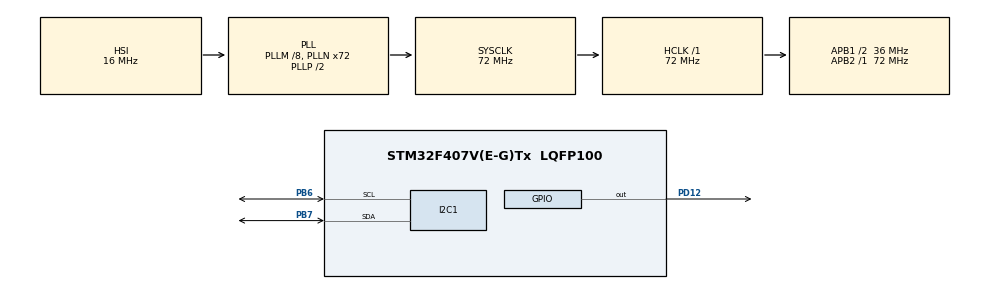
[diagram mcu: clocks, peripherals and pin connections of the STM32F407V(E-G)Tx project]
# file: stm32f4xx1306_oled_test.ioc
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I2C1.I2C_Mode=I2C_Fast
Mcu.Family=STM32F4
Mcu.Name=STM32F407V(E-G)Tx
Mcu.Package=LQFP100
NVIC.PriorityGroup=NVIC_PRIORITYGROUP_4
PB6.Mode=I2C
PB6.Signal=I2C1_SCL
PB7.Mode=I2C
PB7.Signal=I2C1_SDA
PD12.Signal=GPIO_Output
PH0-OSC_IN.Mode=HSE-External-Oscillator
PH0-OSC_IN.Signal=RCC_OSC_IN
PH1-OSC_OUT.Mode=HSE-External-Oscillator
PH1-OSC_OUT.Signal=RCC_OSC_OUT
ProjectManager.HeapSize=0x200
ProjectManager.StackSize=0x400
ProjectManager.TargetToolchain=STM32CubeIDE
RCC.48MHZClocksFreq_Value=36000000
RCC.AHBFreq_Value=72000000
RCC.APB1CLKDivider=RCC_HCLK_DIV2
RCC.APB1Freq_Value=36000000
RCC.APB1TimFreq_Value=72000000
RCC.APB2Freq_Value=72000000
RCC.APB2TimFreq_Value=72000000
RCC.CortexFreq_Value=72000000
RCC.HCLKFreq_Value=72000000
RCC.HSE_VALUE=25000000
RCC.HSI_VALUE=16000000
RCC.LSE_VALUE=32768
RCC.PLLM=8
RCC.PLLN=72
RCC.SYSCLKFreq_VALUE=72000000
RCC.SYSCLKSource=RCC_SYSCLKSOURCE_PLLCLK
RCC.VCOOutputFreq_Value=144000000
board=STM32F407G-DISC1

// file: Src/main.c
/* USER CODE BEGIN Header */
/**
  ******************************************************************************
  * @file           : main.c
  * @brief          : Main program body
  ******************************************************************************
  * @attention
  *
  * <h2><center>&copy; Copyright (c) 2020 STMicroelectronics.
  * All rights reserved.</center></h2>
  *
  * This software component is licensed by ST under BSD 3-Clause license,
  * the "License"; You may not use this file except in compliance with the
  * License. You may obtain a copy of the License at:
  *                        opensource.org/licenses/BSD-3-Clause
  *
  ******************************************************************************
  */
/* USER CODE END Header */

#include "main.h"

/* USER CODE BEGIN Includes */
#include "ssd1306.h"
#include "fonts.h"
#include "test.h"
/* USER CODE END Includes */

I2C_HandleTypeDef hi2c1;

void SystemClock_Config(void);
static void MX_GPIO_Init(void);
static void MX_I2C1_Init(void);

int main(void)
{

  /* MCU Configuration--------------------------------------------------------*/

  /* Reset of all peripherals, Initializes the Flash interface and the Systick. */
  HAL_Init();

  /* Configure the system clock */
  SystemClock_Config();

  /* Initialize all configured peripherals */
  MX_GPIO_Init();
  MX_I2C1_Init();
  /* USER CODE BEGIN 2 */
  SSD1306_Init (); // initialize the diaply

  /* USER CODE END 2 */

  /* Infinite loop */
  while (1)
  {

    /* USER CODE BEGIN 3 */
	  HAL_GPIO_TogglePin(GPIOD, GPIO_PIN_12);
	  HAL_Delay(200);

	  SSD1306_GotoXY (10,10); // goto 10, 10
	  SSD1306_Puts ("HELLO", &Font_11x18, 1); // print Hello
	  SSD1306_GotoXY (10, 30);
	  SSD1306_Puts ("I am Abhinav!!", &Font_7x10, 1);
	  SSD1306_UpdateScreen(); // update screen
//	  0x0000, 0x0000, 0x4400, 0x4400, 0x7C00, 0x2800, 0x2800, 0x2800, 0x2800, 0x1000,  // A
	  //0x1000, 0x2800, 0x2800, 0x2800, 0x2800, 0x7C00, 0x4400, 0x4400, 0x0000, 0x0000,  // A

	  SSD1306_ScrollRight(0x00, 0xff); // Scroll entire Screen screen right is divided in 7 pages (0x00 to 0xff)
	  HAL_Delay(20000);

	  SSD1306_ScrollRight(0x00, 0xff); // Scroll entire Screen screen left is divided in 7 pages (0x00 to 0xff)
	  HAL_Delay(20000);

	  SSD1306_Stopscroll();
	  SSD1306_Clear();
  }
  /* USER CODE END 3 */
}

void SystemClock_Config(void)
{
  RCC_OscInitTypeDef RCC_OscInitStruct = {0};
  RCC_ClkInitTypeDef RCC_ClkInitStruct = {0};

  /** Configure the main internal regulator output voltage
  */
  __HAL_RCC_PWR_CLK_ENABLE();
  __HAL_PWR_VOLTAGESCALING_CONFIG(PWR_REGULATOR_VOLTAGE_SCALE1);
  /** Initializes the CPU, AHB and APB busses clocks
  */
  RCC_OscInitStruct.OscillatorType = RCC_OSCILLATORTYPE_HSI;
  RCC_OscInitStruct.HSIState = RCC_HSI_ON;
  RCC_OscInitStruct.HSICalibrationValue = RCC_HSICALIBRATION_DEFAULT;
  RCC_OscInitStruct.PLL.PLLState = RCC_PLL_ON;
  RCC_OscInitStruct.PLL.PLLSource = RCC_PLLSOURCE_HSI;
  RCC_OscInitStruct.PLL.PLLM = 8;
  RCC_OscInitStruct.PLL.PLLN = 72;
  RCC_OscInitStruct.PLL.PLLP = RCC_PLLP_DIV2;
  RCC_OscInitStruct.PLL.PLLQ = 4;
  if (HAL_RCC_OscConfig(&RCC_OscInitStruct) != HAL_OK)
  {
    Error_Handler();
  }
  /** Initializes the CPU, AHB and APB busses clocks
  */
  RCC_ClkInitStruct.ClockType = RCC_CLOCKTYPE_HCLK|RCC_CLOCKTYPE_SYSCLK
                              |RCC_CLOCKTYPE_PCLK1|RCC_CLOCKTYPE_PCLK2;
  RCC_ClkInitStruct.SYSCLKSource = RCC_SYSCLKSOURCE_PLLCLK;
  RCC_ClkInitStruct.AHBCLKDivider = RCC_SYSCLK_DIV1;
  RCC_ClkInitStruct.APB1CLKDivider = RCC_HCLK_DIV2;
  RCC_ClkInitStruct.APB2CLKDivider = RCC_HCLK_DIV1;

  if (HAL_RCC_ClockConfig(&RCC_ClkInitStruct, FLASH_LATENCY_2) != HAL_OK)
  {
    Error_Handler();
  }
}

static void MX_I2C1_Init(void)
{

  hi2c1.Instance = I2C1;
  hi2c1.Init.ClockSpeed = 400000;
  hi2c1.Init.DutyCycle = I2C_DUTYCYCLE_2;
  hi2c1.Init.OwnAddress1 = 0;
  hi2c1.Init.AddressingMode = I2C_ADDRESSINGMODE_7BIT;
  hi2c1.Init.DualAddressMode = I2C_DUALADDRESS_DISABLE;
  hi2c1.Init.OwnAddress2 = 0;
  hi2c1.Init.GeneralCallMode = I2C_GENERALCALL_DISABLE;
  hi2c1.Init.NoStretchMode = I2C_NOSTRETCH_DISABLE;
  if (HAL_I2C_Init(&hi2c1) != HAL_OK)
  {
    Error_Handler();
  }

}

static void MX_GPIO_Init(void)
{
  GPIO_InitTypeDef GPIO_InitStruct = {0};

  /* GPIO Ports Clock Enable */
  __HAL_RCC_GPIOH_CLK_ENABLE();
  __HAL_RCC_GPIOD_CLK_ENABLE();
  __HAL_RCC_GPIOB_CLK_ENABLE();

  /*Configure GPIO pin Output Level */
  HAL_GPIO_WritePin(GPIOD, GPIO_PIN_12, GPIO_PIN_RESET);

  /*Configure GPIO pin : PD12 */
  GPIO_InitStruct.Pin = GPIO_PIN_12;
  GPIO_InitStruct.Mode = GPIO_MODE_OUTPUT_PP;
  GPIO_InitStruct.Pull = GPIO_NOPULL;
  GPIO_InitStruct.Speed = GPIO_SPEED_FREQ_LOW;
  HAL_GPIO_Init(GPIOD, &GPIO_InitStruct);

}

void Error_Handler(void)
{
}

/************************ (C) COPYRIGHT STMicroelectronics *****END OF FILE****/
